# PIC18F24Q24 register map
Vendor: Microchip
Registers are 8-bit, read-write, reset 0x0 unless marked. A register's access mark holds for its fields unless they carry their own. Addresses are absolute, and some are shared; only a register's first bit layout is shown; [hi:lo] are bit positions; {n}, {i} and the like mark numbered series; 'fields as' and 'values as' point back to an identical list.

## tmr
0x312 TMR1L
0x313 TMR1H
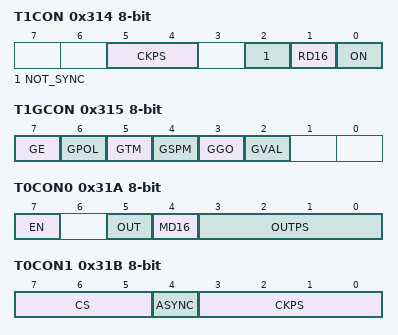
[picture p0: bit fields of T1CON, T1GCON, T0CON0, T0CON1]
0x314 T1CON
  [5:4] CKPS, [2] NOT_SYNC, [1] RD16, [0] ON
0x315 T1GCON reset not defined — (power-on value 00000x--)
  [7] GE, [6] GPOL, [5] GTM, [4] GSPM, [3] GGO, [2] GVAL ro
0x316 T1GATE
  [4:0] GSS
0x317 T1CLK
  [4:0] CS
0x318 TMR0L
0x319 TMR0H reset 0xFF
0x31A T0CON0
  [7] EN, [5] OUT ro, [4] MD16, [3:0] OUTPS
0x31B T0CON1
  [7:5] CS, [4] ASYNC, [3:0] CKPS
0x31D T2TMR — 8-bit period timer
  [7:0] TMR2
0x31E T2PR reset 0xFF
  [7:0] PR2
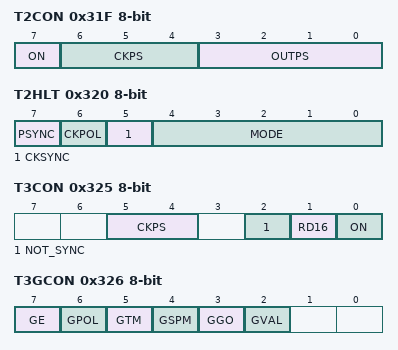
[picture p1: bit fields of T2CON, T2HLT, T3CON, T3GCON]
0x31F T2CON
  [7] ON, [6:4] CKPS, [3:0] OUTPS
0x320 T2HLT
  [7] PSYNC, [6] CKPOL, [5] CKSYNC, [4:0] MODE
0x321 T2CLKCON
  [4:0] CS
0x322 T2RST
  [4:0] RSEL
0x323 TMR3L
0x324 TMR3H
0x325 T3CON
  [5:4] CKPS, [2] NOT_SYNC, [1] RD16, [0] ON
0x326 T3GCON reset not defined — (power-on value 00000x--)
  [7] GE, [6] GPOL, [5] GTM, [4] GSPM, [3] GGO, [2] GVAL ro
0x327 T3GATE
  [4:0] GSS
0x328 T3CLK
  [4:0] CS
0x32A T4TMR — 8-bit period timer
  [7:0] TMR4
0x32B T4PR reset 0xFF
  [7:0] PR4
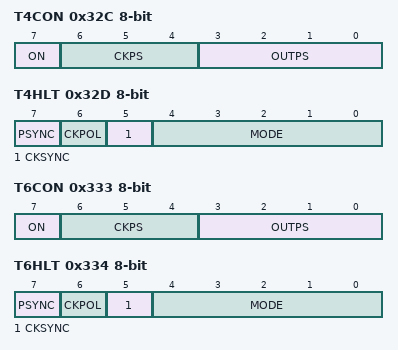
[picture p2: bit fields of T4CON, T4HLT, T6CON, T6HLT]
0x32C T4CON
  [7] ON, [6:4] CKPS, [3:0] OUTPS
0x32D T4HLT
  [7] PSYNC, [6] CKPOL, [5] CKSYNC, [4:0] MODE
0x32E T4CLKCON
  [4:0] CS
0x32F T4RST
  [4:0] RSEL
0x331 T6TMR — 8-bit period timer
  [7:0] TMR6
0x332 T6PR reset 0xFF
  [7:0] PR6
0x333 T6CON
  [7] ON, [6:4] CKPS, [3:0] OUTPS
0x334 T6HLT
  [7] PSYNC, [6] CKPOL, [5] CKSYNC, [4:0] MODE
0x335 T6CLKCON
  [4:0] CS
0x336 T6RST
  [4:0] RSEL
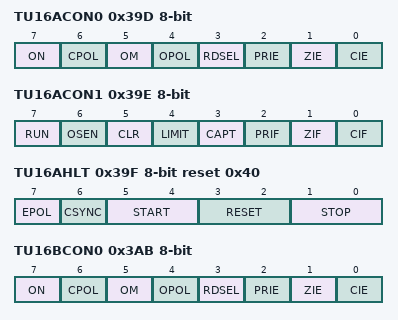
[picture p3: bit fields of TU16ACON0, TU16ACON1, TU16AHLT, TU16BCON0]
0x39D TU16ACON0
  [7] ON, [6] CPOL, [5] OM, [4] OPOL, [3] RDSEL, [2] PRIE, [1] ZIE, [0] CIE
0x39E TU16ACON1
  [7] RUN ro, [6] OSEN, [5] CLR, [4] LIMIT, [3] CAPT, [2] PRIF, [1] ZIF, [0] CIF
0x39F TU16AHLT reset 0x40
  [7] EPOL, [6] CSYNC, [5:4] START, [3:2] RESET, [1:0] STOP
0x3A0 TU16APS
  [7:0] PS
0x3A5 TU16APRL reset 0xFF
  [7:0] PRL
0x3A6 TU16APRH reset 0xFF
  [7:0] PRH
0x3A8 TU16APRT reset 0xFF
  [7:0] PRT
0x3A9 TU16ACLK
  [4:0] CLK
0x3AA TU16AERS
  [5:0] ERS
0x3AB TU16BCON0
  fields as TU16ACON0
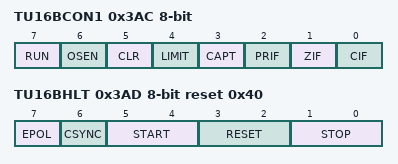
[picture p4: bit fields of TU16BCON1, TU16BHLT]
0x3AC TU16BCON1
  fields as TU16ACON1
0x3AD TU16BHLT reset 0x40
  [7] EPOL, [6] CSYNC, [5:4] START, [3:2] RESET, [1:0] STOP
0x3AE TU16BPS
  [7:0] PS
0x3B3 TU16BPRL reset 0xFF
  [7:0] PRL
0x3B4 TU16BPRH reset 0xFF
  [7:0] PRH
0x3B6 TU16BPRT reset 0xFF
  [7:0] PRT
0x3B7 TU16BCLK
  [4:0] CLK
0x3B8 TU16BERS
  [5:0] ERS

## ccp
0x340 CCPR1L reset not defined — (power-on value xxxxxxxx)
  [7:0] RL
0x341 CCPR1H reset not defined — (power-on value xxxxxxxx)
  [7:0] RH
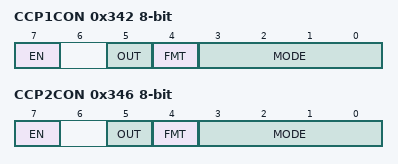
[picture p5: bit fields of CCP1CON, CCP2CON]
0x342 CCP1CON
  [7] EN, [5] OUT ro, [4] FMT, [3:0] MODE
0x343 CCP1CAP
  [3:0] CTS
0x344 CCPR2L reset not defined — (power-on value xxxxxxxx)
  [7:0] RL
0x345 CCPR2H reset not defined — (power-on value xxxxxxxx)
  [7:0] RH
0x346 CCP2CON
  [7] EN, [5] OUT ro, [4] FMT, [3:0] MODE
0x347 CCP2CAP
  [3:0] CTS

## math_progcrc
0x34E CRCDATAL
  [7:0] DATA
0x34F CRCDATAH
  [7:0] DATA
0x350 CRCDATAU
  [7:0] DATA
0x351 CRCDATAT
  [7:0] DATA
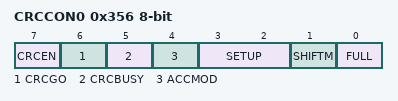
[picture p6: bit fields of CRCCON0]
0x356 CRCCON0
  [7] CRCEN, [6] CRCGO, [5] CRCBUSY ro, [4] ACCMOD, [3:2] SETUP, [1] SHIFTM, [0] FULL ro
0x357 CRCCON1
  [4:0] PLEN
0x358 CRCCON2
  [4:0] DLEN

## nvm_scan
0x35A SCANLADRL
  [7:0] LADR
0x35B SCANLADRH
  [7:0] LADR
0x35C SCANLADRU
  [5:0] LADR
0x35D SCANHADRL reset 0xFF
  [7:0] HADR
0x35E SCANHADRH reset 0xFF
  [7:0] HADR
0x35F SCANHADRU reset 0x3F
  [5:0] HADR
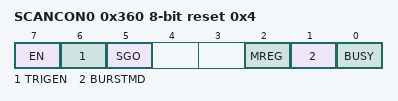
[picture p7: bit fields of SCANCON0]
0x360 SCANCON0 reset 0x4
  [7] EN, [6] TRIGEN, [5] SGO, [2] MREG, [1] BURSTMD, [0] BUSY
0x361 SCANTRIG
  [4:0] TSEL

## wg_ecwg
0x3BC CWG1CLK
  [0] CS
0x3BD CWG1ISM
  [4:0] ISM
0x3BE CWG1DBR
  [5:0] DBR
0x3BF CWG1DBF
  [5:0] DBF
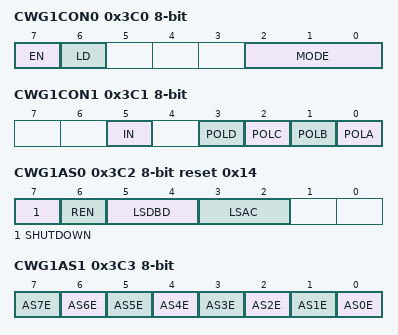
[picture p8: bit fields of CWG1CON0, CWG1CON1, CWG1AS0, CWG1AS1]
0x3C0 CWG1CON0
  [7] EN, [6] LD, [2:0] MODE
0x3C1 CWG1CON1 reset not defined — (power-on value --x-0000)
  [5] IN ro, [3] POLD, [2] POLC, [1] POLB, [0] POLA
0x3C2 CWG1AS0 reset 0x14
  [7] SHUTDOWN, [6] REN, [5:4] LSDBD, [3:2] LSAC
0x3C3 CWG1AS1
  [n] AS{n}E (n=0..7)
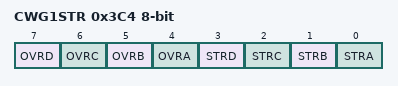
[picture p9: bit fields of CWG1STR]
0x3C4 CWG1STR
  [7] OVRD, [6] OVRC, [5] OVRB, [4] OVRA, [3] STRD, [2] STRC, [1] STRB, [0] STRA

## amp_fvr_ts_ctrl
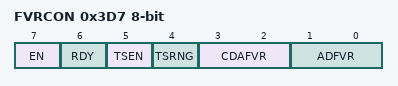
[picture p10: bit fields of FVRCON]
0x3D7 FVRCON reset not defined — (power-on value xx000000)
  [7] EN — Zero-Cross Detect Software Enable bit
  [6] RDY ro
  [5] TSEN — Zero-Cross Detect Data Output
  [4] TSRNG — Zero-Cross Detect Polarity bit
  [3:2] CDAFVR
  [1:0] ADFVR — Zero-Cross Detect Positive-going Edge Interrupt Enable

## DOS_xxxxx_port_control
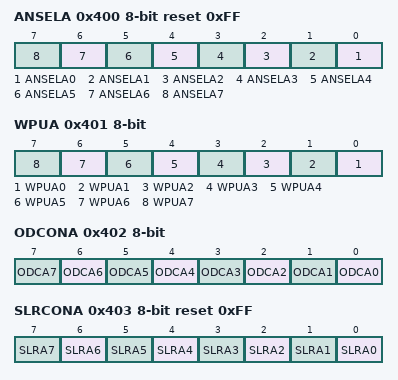
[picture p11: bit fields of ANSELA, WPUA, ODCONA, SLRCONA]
0x400 ANSELA reset 0xFF
  [n] ANSELA{n} (n=0..7)
0x401 WPUA
  [n] WPUA{n} (n=0..7)
0x402 ODCONA
  [n] ODCA{n} (n=0..7)
0x403 SLRCONA reset 0xFF
  [n] SLRA{n} (n=0..7)
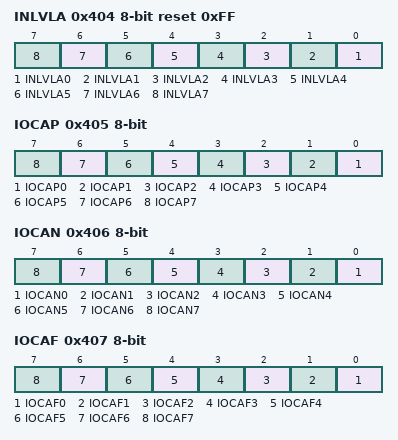
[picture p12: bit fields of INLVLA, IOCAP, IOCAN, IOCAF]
0x404 INLVLA reset 0xFF
  [n] INLVLA{n} (n=0..7)
0x405 IOCAP
  [n] IOCAP{n} (n=0..7)
0x406 IOCAN
  [n] IOCAN{n} (n=0..7)
0x407 IOCAF
  [n] IOCAF{n} (n=0..7)
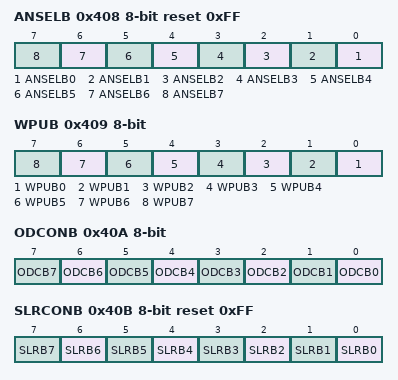
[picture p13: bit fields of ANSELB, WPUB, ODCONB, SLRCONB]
0x408 ANSELB reset 0xFF
  [n] ANSELB{n} (n=0..7)
0x409 WPUB
  [n] WPUB{n} (n=0..7)
0x40A ODCONB
  [n] ODCB{n} (n=0..7)
0x40B SLRCONB reset 0xFF
  [n] SLRB{n} (n=0..7)
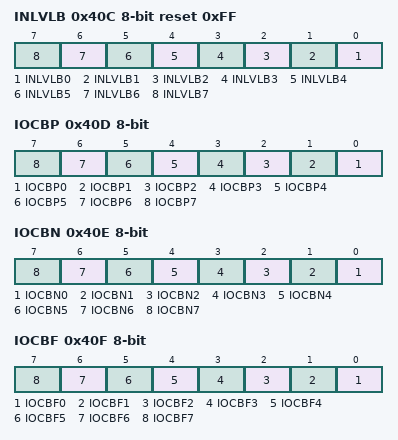
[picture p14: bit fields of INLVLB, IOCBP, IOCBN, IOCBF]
0x40C INLVLB reset 0xFF
  [n] INLVLB{n} (n=0..7)
0x40D IOCBP
  [n] IOCBP{n} (n=0..7)
0x40E IOCBN
  [n] IOCBN{n} (n=0..7)
0x40F IOCBF
  [n] IOCBF{n} (n=0..7)
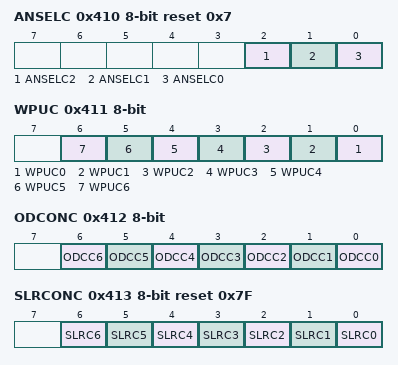
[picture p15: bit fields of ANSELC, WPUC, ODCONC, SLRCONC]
0x410 ANSELC reset 0x7
  [2] ANSELC2, [1] ANSELC1, [0] ANSELC0
0x411 WPUC
  [n] WPUC{n} (n=0..6)
0x412 ODCONC
  [n] ODCC{n} (n=0..6)
0x413 SLRCONC reset 0x7F
  [n] SLRC{n} (n=0..6)
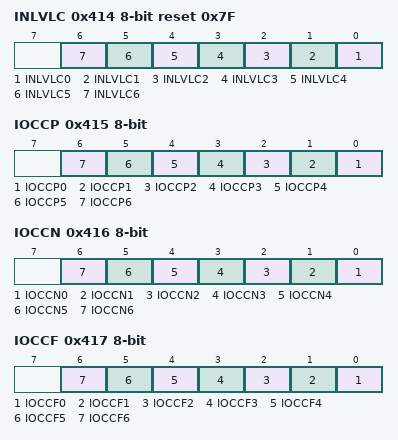
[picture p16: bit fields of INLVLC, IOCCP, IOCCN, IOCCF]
0x414 INLVLC reset 0x7F
  [n] INLVLC{n} (n=0..6)
0x415 IOCCP
  [n] IOCCP{n} (n=0..6)
0x416 IOCCN
  [n] IOCCN{n} (n=0..6)
0x417 IOCCF
  [n] IOCCF{n} (n=0..6)
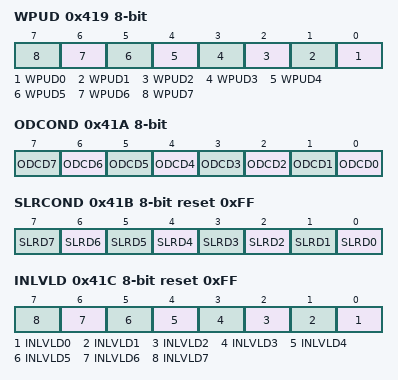
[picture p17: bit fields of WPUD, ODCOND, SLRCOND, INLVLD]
0x419 WPUD
  [n] WPUD{n} (n=0..7)
0x41A ODCOND
  [n] ODCD{n} (n=0..7)
0x41B SLRCOND reset 0xFF
  [n] SLRD{n} (n=0..7)
0x41C INLVLD reset 0xFF
  [n] INLVLD{n} (n=0..7)
0x41D IOCDP
  [n] IOCDP{n} (n=0..7)
0x41E IOCDN
  [n] IOCDN{n} (n=0..7)
0x41F IOCDF
  [n] IOCDF{n} (n=0..7)
0x420 ANSELE reset 0x7
  [2] ANSELE2, [1] ANSELE1, [0] ANSELE0
0x421 WPUE
  [n] WPUE{n} (n=0..3)
0x422 ODCONE
  [2] ODCE2, [1] ODCE1, [0] ODCE0
0x423 SLRCONE reset 0x7
  [2] SLRE2, [1] SLRE1, [0] SLRE0
0x424 INLVLE reset 0xF
  [n] INLVLE{n} (n=0..3)
0x425 IOCEP
  [3] IOCEP3
0x426 IOCEN
  [3] IOCEN3
0x427 IOCEF
  [3] IOCEF3
0x43D IOCWP
  [n] IOCWP{n} (n=0..7)
0x43E IOCWN
  [n] IOCWN{n} (n=0..7)
0x43F IOCWF
  [n] IOCWF{n} (n=0..7)

## tmr_dds
0x440 NCO1ACCL
  [7:0] ACC
0x441 NCO1ACCH
  [7:0] ACC
0x442 NCO1ACCU
  [3:0] ACC
0x443 NCO1INCL reset 0x1
  [7:0] INC
0x444 NCO1INCH
  [7:0] INC
0x445 NCO1INCU
  [3:0] INC
0x446 NCO1CON — Configurable logic cell control
  [7] EN, [5] OUT ro, [4] POL, [0] PFM
0x447 NCO1CLK
  [7:5] PWS, [4:0] CKS

## int
0x459 IVTLOCK
  [0] IVTLOCKED
0x45A IVTADL
  [n] AD{n} (n=0..7)
0x45B IVTADH
  [n-8] AD{n} (n=8..15)
0x45C IVTADU
  [n-16] AD{n} (n=16..20)
0x45D IVTBASEL reset 0x8
  [n] BASE{n} (n=0..7)
0x45E IVTBASEH
  [n-8] BASE{n} (n=8..15)
0x45F IVTBASEU
  [n-16] BASE{n} (n=16..20)
0x4D6 INTCON0 reset 0x7
  [7] GIE, [6] GIEL, [5] IPEN, [2] INT2EDG, [1] INT1EDG, [0] INT0EDG
0x4D7 INTCON1 ro
  [7:6] STAT

## pwm_cmp
{0x451+0xF*i} PWM{i}ERS (i=1..3)
  [3:0] ERS
{0x452+0xF*i} PWM{i}CLK (i=1..3)
  [4:0] CLK
{0x453+0xF*i} PWM{i}LDS (i=1..3)
  [3:0] LDS
{0x454+0xF*i} PWM{i}PRL (i=1..3)
  [7:0] PRL
{0x455+0xF*i} PWM{i}PRH (i=1..3)
  [7:0] PRH
{0x456+0xF*i} PWM{i}CPRE (i=1..3)
  [7:0] CPRE
{0x457+0xF*i} PWM{i}PIPOS (i=1..3)
  [7:0] PIPOS
{0x458+0xF*i} PWM{i}GIR (i=1..3)
  [1] S1P2IF, [0] S1P1IF
{0x459+0xF*i} PWM{i}GIE (i=1..3)
  [1] S1P2IE, [0] S1P1IE
{0x45A+0xF*i} PWM{i}CON (i=1..3)
  [7] EN, [2] LD, [1] ERSPOL, [0] ERSNOW
{0x45B+0xF*i} PWM{i}S1CFG (i=1..3)
  [7] POL2, [6] POL1, [3] PPEN, [2:0] MODE
{0x45C+0xF*i} PWM{i}S1P1L (i=1..3)
  [7:0] S1P1L
{0x45D+0xF*i} PWM{i}S1P1H (i=1..3)
  [7:0] S1P1H
{0x45E+0xF*i} PWM{i}S1P2L (i=1..3)
  [7:0] S1P2L
{0x45F+0xF*i} PWM{i}S1P2H (i=1..3)
  [7:0] S1P2H
